# CY8C5888LTI_LP097 register map
File version: 0.1
CY8C58LP
Registers are 8-bit, read-write, no defined reset value unless marked. A register's access mark holds for its fields unless they carry their own. Offsets are from the block's base; lines under a group give offsets from that group; [hi:lo] are bit positions; {n}, {i} and the like mark numbered series; 'fields as' and 'values as' point back to an identical list; <NAME> marks a mode.

## Memory map
0x00000000 PWM_Y
0x00000000 PWM_Z
0x00000000 SPIS_1
0x00000000 ADC_SAR_Seq_SAR — SAR ADC
0x00000000 PWM_X

## PWM_Y
Base 0x00000000
0x40006420 PWM_Y_COMPARE_Reg 16-bit — UDB.D0 - Assigned Compare Value
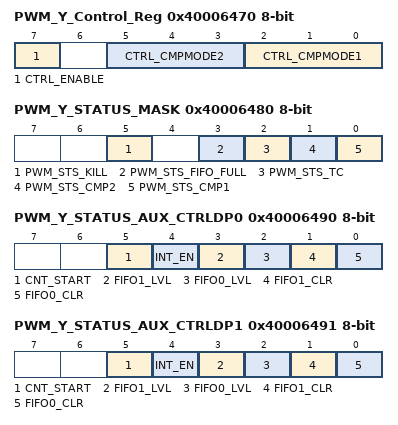
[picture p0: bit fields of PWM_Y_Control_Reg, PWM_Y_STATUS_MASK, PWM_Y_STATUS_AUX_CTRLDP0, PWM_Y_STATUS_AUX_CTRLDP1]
0x40006470 PWM_Y_Control_Reg — UDB Control Register - Assigned Control Register Value
  [7] CTRL_ENABLE — Enable the PWM
  [5:3] CTRL_CMPMODE2 — Compare mode 2
  [2:0] CTRL_CMPMODE1 — Compare mode 1
0x40006480 PWM_Y_STATUS_MASK — UDB Status bits Interrupt Mask Enable Register
  [5] PWM_STS_KILL ro — Enables the Interrupt on Kill
  [3] PWM_STS_FIFO_FULL ro — FIFO Full Status Mask
  [2] PWM_STS_TC ro — Enables the Interrupt on Terminal Count
  [1] PWM_STS_CMP2 ro — Enables the Interrupt on Compare 2
  [0] PWM_STS_CMP1 ro — Enables the Interrupt on Compare 1
0x40006490 PWM_Y_STATUS_AUX_CTRLDP0 — UDB Auxilliary Control Register
  [5] CNT_START — FIFO0 clear
    0=E_CNT_START0 (Disable counter); 1=E_CNT_START1 (Enable counter)
  [4] INT_EN
    0=E_INT_EN0 (Interrupt disabled); 1=E_INT_EN1 (Interrupt enabled)
  [3] FIFO1_LVL — FIFO level
    0=E_FIFO_LVL_0 (FIFO LVL: input mode: FIFO not full; output mode: FIFO not empty); 1=E_FIFO_LVL_1 (FIFO LVL: input mode: FIFO at least 1/2 empty; output mode: FIFO at least 1/2 full)
  [2] FIFO0_LVL — FIFO level
    values as FIFO1_LVL
  [1] FIFO1_CLR — FIFO1 clear
    0=E_FIFO_CLR_0 (Normal FIFO operation); 1=E_FIFO_CLR_1 (Clear FIFO state)
  [0] FIFO0_CLR — FIFO0 clear
    values as FIFO1_CLR
0x40006491 PWM_Y_STATUS_AUX_CTRLDP1 — UDB Auxilliary Control Register
  fields as PWM_Y_STATUS_AUX_CTRLDP0

## PWM_Z
Base 0x00000000
0x40006428 PWM_Z_COMPARE_Reg 16-bit — UDB.D0 - Assigned Compare Value
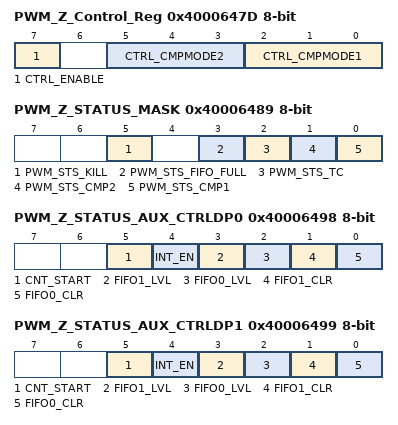
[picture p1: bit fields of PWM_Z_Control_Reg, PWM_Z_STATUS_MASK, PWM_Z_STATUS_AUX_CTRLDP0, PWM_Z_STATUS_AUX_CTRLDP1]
0x4000647D PWM_Z_Control_Reg — UDB Control Register - Assigned Control Register Value
  [7] CTRL_ENABLE — Enable the PWM
  [5:3] CTRL_CMPMODE2 — Compare mode 2
  [2:0] CTRL_CMPMODE1 — Compare mode 1
0x40006489 PWM_Z_STATUS_MASK — UDB Status bits Interrupt Mask Enable Register
  fields as PWM_Y.PWM_Y_STATUS_MASK
0x40006498 PWM_Z_STATUS_AUX_CTRLDP0 — UDB Auxilliary Control Register
  fields as PWM_Y.PWM_Y_STATUS_AUX_CTRLDP0
0x40006499 PWM_Z_STATUS_AUX_CTRLDP1 — UDB Auxilliary Control Register
  fields as PWM_Y.PWM_Y_STATUS_AUX_CTRLDP0

## SPIS_1
Base 0x00000000
0x40006405 SPIS_1_RX_DATA — SPIS RX Data
0x40006405 SPIS_1_TX_DATA — SPIS TX Data
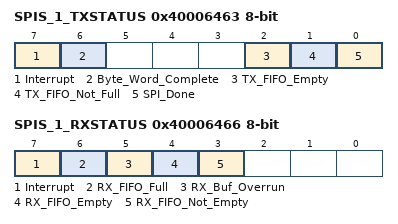
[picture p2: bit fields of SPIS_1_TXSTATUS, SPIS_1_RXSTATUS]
0x40006463 SPIS_1_TXSTATUS — SPIS TX Status Register
  [7] Interrupt ro — Set when interrupt occurs
  [6] Byte_Word_Complete ro — Set when a byte/word transmit has completed
  [2] TX_FIFO_Empty ro — Set when the TX Data FIFO is empty
  [1] TX_FIFO_Not_Full ro — Set when the TX Data FIFO is not full
  [0] SPI_Done ro — Set when all of the data in the transmit FIFO has been sent. Set when Byte/Word Complete has been set and TX Data FIFO is empty
0x40006466 SPIS_1_RXSTATUS — SPIS RX Status Register
  [7] Interrupt ro — Set when interrupt occurs
  [6] RX_FIFO_Full ro — Set when the RX Data FIFO is full
  [5] RX_Buf_Overrun ro — Set when RX Data has overrun the 4 byte/word FIFO without being moved to the RX buffer cmemory array (if one exists)
  [4] RX_FIFO_Empty ro — Set when the RX Data FIFO is empty
  [3] RX_FIFO_Not_Empty ro — Set when the RX Data FIFO is not empty. That is, at least one byte/word is in the RX FIFO

## ADC_SAR_Seq_SAR — SAR ADC
Base 0x00000000
0x40004616 SAR_TR0 — SAR trim register
{0x40005908+i} SAR_CSR{i} (i=0..6) — SAR status and control register {i}
0x40005B28 SAR_SW0 — SAR Analog Routing Register 0
{0x40005B28+i} SAR_SW{i} (i=2..4) — SAR Analog Routing Register {i}
0x40005B2E SAR_SW6 — SAR Analog Routing Register 6
0x40005B2F SAR_CLK — SAR Clock Selection Register
0x40005BA2 SAR_WRK 16-bit — SAR working register

## PWM_X
Base 0x00000000
0x40006524 PWM_X_COMPARE_Reg 16-bit — UDB.D0 - Assigned Compare Value
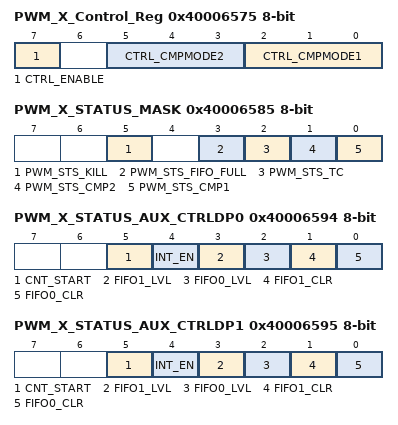
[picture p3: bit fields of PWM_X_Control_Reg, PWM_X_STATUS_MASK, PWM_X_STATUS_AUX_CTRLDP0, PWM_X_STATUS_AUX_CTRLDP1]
0x40006575 PWM_X_Control_Reg — UDB Control Register - Assigned Control Register Value
  [7] CTRL_ENABLE — Enable the PWM
  [5:3] CTRL_CMPMODE2 — Compare mode 2
  [2:0] CTRL_CMPMODE1 — Compare mode 1
0x40006585 PWM_X_STATUS_MASK — UDB Status bits Interrupt Mask Enable Register
  fields as PWM_Y.PWM_Y_STATUS_MASK
0x40006594 PWM_X_STATUS_AUX_CTRLDP0 — UDB Auxilliary Control Register
  fields as PWM_Y.PWM_Y_STATUS_AUX_CTRLDP0
0x40006595 PWM_X_STATUS_AUX_CTRLDP1 — UDB Auxilliary Control Register
  fields as PWM_Y.PWM_Y_STATUS_AUX_CTRLDP0
